# STM32N647 register map
File version: 1.0
CPU: CM55 r0p1, little endian, no MPU, FPU, vendor SysTick, 8 interrupt priority bits
Registers are 32-bit, read-write, reset 0x0 unless marked. A register's access mark holds for its fields unless they carry their own. Offsets are from the block's base; [hi:lo] are bit positions; {n}, {i} and the like mark numbered series.

## DLYBSD — DLYBSD address block description
Base 0x48028000
Same registers: DLYBSD2 0x48026C00, DLYBSD2_S 0x58026C00, DLYBSD_S 0x58028000
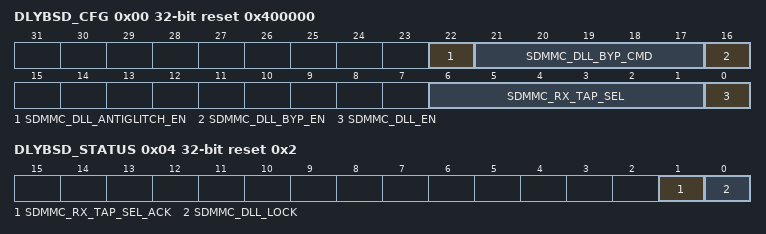
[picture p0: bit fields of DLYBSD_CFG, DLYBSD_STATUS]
0x00 DLYBSD_CFG reset 0x400000 — Delay block SDMMC DLL configuration
  [22] SDMMC_DLL_ANTIGLITCH_EN — Antiglitch logic enabled when 1
  [21:17] SDMMC_DLL_BYP_CMD — Bypass command
  [16] SDMMC_DLL_BYP_EN — DLL configuration
    0=Lock mode; 1=Pure delay
  [6:1] SDMMC_RX_TAP_SEL — selection of RX delay
  [0] SDMMC_DLL_EN — DLL enable
0x04 DLYBSD_STATUS reset 0x2 — Delay block SDMMC DLL status
  [1] SDMMC_RX_TAP_SEL_ACK — SDMMC RX delay selection acknowledge
  [0] SDMMC_DLL_LOCK

## GFXMMU — Chrom-GRC
Base 0x48030000
Same registers: GFXMMU_S 0x58030000
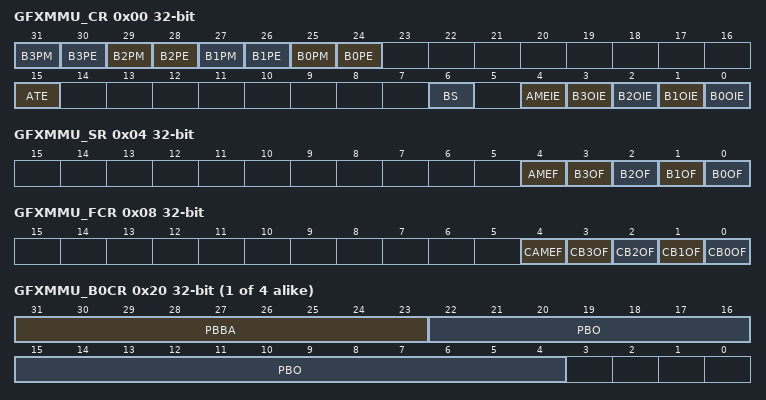
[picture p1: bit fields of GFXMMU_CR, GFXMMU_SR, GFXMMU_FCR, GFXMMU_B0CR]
0x00 GFXMMU_CR — GFXMMU configuration register
  [2n+25] B{n}PM (n=0..3) — Buffer {n} packing mode
    0=MSB is removed; 1=LSB is removed
  [2n+24] B{n}PE (n=0..3) — Buffer {n} packing enable
    0=Packing is disabled; 1=Packing is enable
  [15] ATE — Address translation enable
    0=Address translation is disable; 1=Address translation is enable
  [6] BS — Block size
    0=16-byte blocks; 1=12-byte blocks
  [4] AMEIE — AXI master error interrupt enable
    0=Interrupt disable; 1=Interrupt enabled
  [n] B{n}OIE (n=0..3) — Buffer {n} overflow interrupt enable
    0=Interrupt disable; 1=Interrupt enabled
0x04 GFXMMU_SR ro — GFXMMU status register
  [4] AMEF — AXI master error flag
  [n] B{n}OF (n=0..3) — Buffer {n} overflow flag
0x08 GFXMMU_FCR — GFXMMU flag clear register
  [4] CAMEF — Clear AXI master error flag
  [n] CB{n}OF (n=0..3) — Clear buffer {n} overflow flag
0x10 GFXMMU_DVR — GFXMMU default value register
  [31:0] DV — Default value
0x14 GFXMMU_DAR — GFXMMU default alpha register
  [7:0] DA — Default alpha
{0x20+4i} GFXMMU_B{i}CR (i=0..3) — GFXMMU buffer {i} configuration register
  [31:23] PBBA — Physical buffer base address
  [22:4] PBO — Physical buffer offset
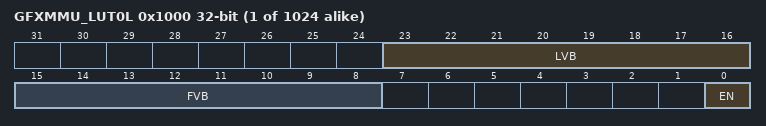
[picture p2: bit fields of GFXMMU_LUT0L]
{0x1000+8i} GFXMMU_LUT{i}L (i=0..1023) — GFXMMU LUT entry {i} low
  [23:16] LVB — Last valid block
  [15:8] FVB — First valid block
  [0] EN — Enable
    0=Line is disabled (no MMU evaluation is performed); 1=Line is enabled (MMU evaluation is performed)
{0x1004+8i} GFXMMU_LUT{i}H (i=0..1023) — GFXMMU LUT entry {i} high
  [17:0] LO — Line offset

## HDP — Hardware debug port
Base 0x46000800
Same registers: HDP_S 0x56000800
0x00 HDP_CTRL — HDP control register
  [0] EN — Enable HDP, valid if enabled in BSEC
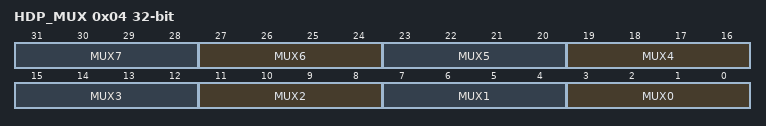
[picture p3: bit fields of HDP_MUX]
0x04 HDP_MUX — HDP multiplexer control register
  [4n+3:4n] MUX{n} (n=0..7) — Select the HDPy output among the 16 available signals
0x10 HDP_VAL ro — HDP read back value register
  [7:0] HDPVAL — Value of the HDP signals
0x14 HDP_GPOSET wo — HDP general-purpose output set register
  [7:0] HDPGPOSET — When a bit is written to 1, the corresponding HDP GPO is set
0x18 HDP_GPOCLR wo — HDP general purpose output clear register
  [7:0] HDPGPOCLR — When a bit is written to 1, the corresponding HDP GPO is cleared.
0x1C HDP_GPOVAL — HDP general purpose output value register
  [7:0] HDPGPOVAL — When written, define the value of the HDP GPO.

## ICACHE — Texture cache
Base 0x48035000
Same registers: ICACHE_S 0x58035000
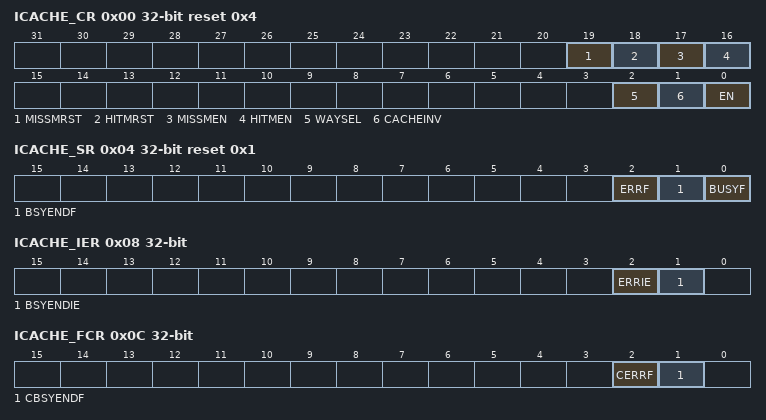
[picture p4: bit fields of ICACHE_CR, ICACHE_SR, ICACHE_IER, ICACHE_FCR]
0x00 ICACHE_CR access per field reset 0x4 — ICACHE control register
  [19] MISSMRST rw — miss monitor reset
    0=no effect; 1=reset cache miss monitor
  [18] HITMRST rw — hit monitor reset
    0=no effect; 1=reset cache hit monitor
  [17] MISSMEN rw — miss monitor enable
    0=cache miss monitor switched off. Stopping the monitor does not reset it.; 1=cache miss monitor enabled
  [16] HITMEN rw — hit monitor enable
    0=cache hit monitor switched off. Stopping the monitor does not reset it.; 1=cache hit monitor enabled
  [2] WAYSEL rw — cache associativity mode selection
    0=direct mapped cache (1-way cache); 1=n-way set associative cache (reset value)
  [1] CACHEINV wo — cache invalidation
    0=no effect; 1=invalidate entire cache (all cache lines valid bit = 0)
  [0] EN rw — enable
    0=cache disabled; 1=cache enabled
0x04 ICACHE_SR ro reset 0x1 — ICACHE status register
  [2] ERRF — cache error flag
    0=no error; 1=an error occurred during the operation (cacheable write)
  [1] BSYENDF — busy end flag
    0=cache busy; 1=full invalidate CACHEINV operation finished
  [0] BUSYF — busy flag
    0=cache not busy on a CACHEINV operation; 1=cache executing a full invalidate CACHEINV operation
0x08 ICACHE_IER — ICACHE interrupt enable register
  [2] ERRIE — interrupt enable on cache error
    0=interrupt disabled on error; 1=interrupt enabled on error
  [1] BSYENDIE — interrupt enable on busy end
    0=interrupt disabled on busy end; 1=interrupt enabled on busy end
0x0C ICACHE_FCR wo — ICACHE flag clear register
  [2] CERRF — clear cache error flag
    0=no effect; 1=clears ERRF flag in ICACHE_SR
  [1] CBSYENDF — clear busy end flag
    0=no effect; 1=clears BSYENDF flag in ICACHE_SR
0x10 ICACHE_HMONR ro — ICACHE hit monitor register
  [31:0] HITMON — cache hit monitor counter
0x14 ICACHE_MMONR ro — ICACHE miss monitor register
  [15:0] MISSMON — cache miss monitor counter
